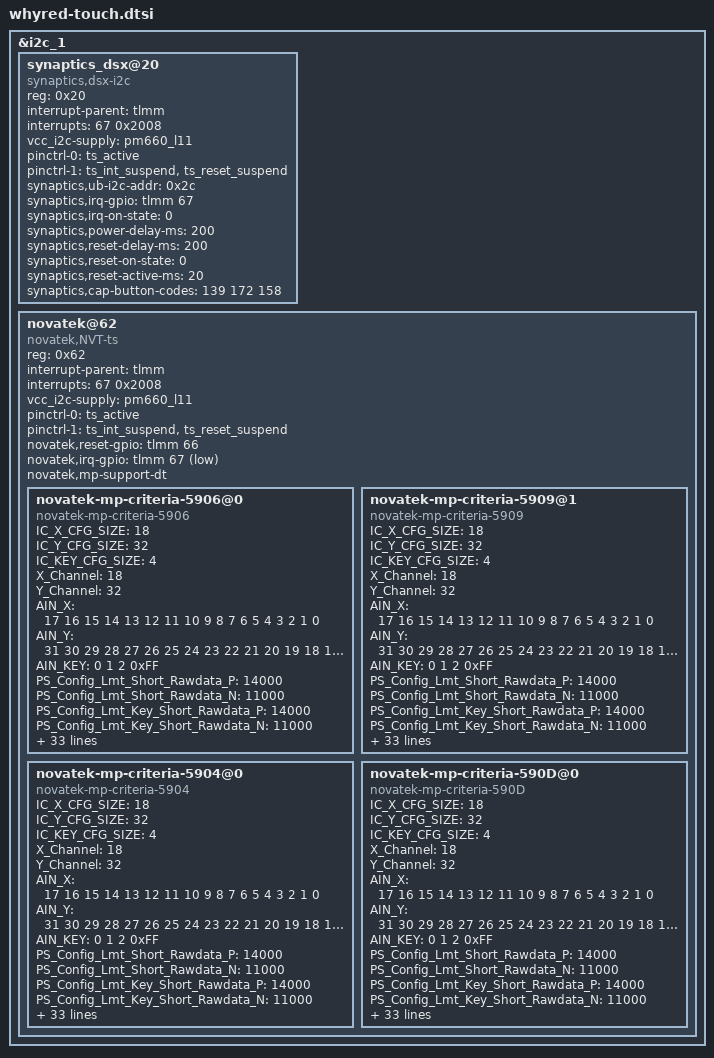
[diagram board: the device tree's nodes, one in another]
/* Copyright (c) 2017, The Linux Foundation. All rights reserved.
 * Copyright (C) 2019 XiaoMi, Inc.
 *
 * This program is free software; you can redistribute it and/or modify
 * it under the terms of the GNU General Public License version 2 and
 * only version 2 as published by the Free Software Foundation.
 *
 * This program is distributed in the hope that it will be useful,
 * but WITHOUT ANY WARRANTY; without even the implied warranty of
 * MERCHANTABILITY or FITNESS FOR A PARTICULAR PURPOSE.  See the
 * GNU General Public License for more details.
*/

&i2c_1 {
	status = "ok";

	synaptics_dsx@20 {
		compatible = "synaptics,dsx-i2c";
		reg = <0x20>;
		interrupt-parent = <&tlmm>;
		interrupts = <67 0x2008>;
		//vdd-supply = <&pm8994_lvs2>;
		//avdd-supply = <&pm8994_l22>;
		vcc_i2c-supply=<&pm660_l11>;
		pinctrl-names = "pmx_ts_active", "pmx_ts_suspend";
		pinctrl-0 = <&ts_active>;
		pinctrl-1 = <&ts_int_suspend &ts_reset_suspend>;
		//synaptics,pwr-reg-name = "avdd";
		//synaptics,bus-reg-name = "vdd";
		synaptics,ub-i2c-addr = <0x2c>;
		synaptics,irq-gpio = <&tlmm 67 0x2008>; /* IRQF_ONESHOT | IRQF_TRIGGER_LOW */
		//synaptics,reset-gpio = <&tlmm 66 0x00>;
		synaptics,irq-on-state = <0>;
		synaptics,power-delay-ms = <200>;
		synaptics,reset-delay-ms = <200>;
		synaptics,reset-on-state = <0>;
		synaptics,reset-active-ms = <20>;
		/* uncomment and update line below as appropriate if there are 0D buttons */
		synaptics,cap-button-codes = <139 172 158>; 
		/* uncomment and update lines below as appropriate if there are virtual buttons */
		/* synaptics,vir-button-codes = <102 100 900 100 60 158 300 900 100 60>; */
		/* synaptics,max-y-for-2d = <800>; */
	};

	/* Novatek device tree node */
	novatek@62 {
		compatible = "novatek,NVT-ts";
		reg = <0x62>;
		status = "ok";
		interrupt-parent = <&tlmm>;
		interrupts = <67 0x2008>;
		//vdd-supply = <&pm8994_lvs2>;
		//avdd-supply = <&pm8994_l22>;
		vcc_i2c-supply=<&pm660_l11>;
		pinctrl-names = "pmx_ts_active", "pmx_ts_suspend";
		pinctrl-0 = <&ts_active>;
		pinctrl-1 = <&ts_int_suspend &ts_reset_suspend>;
		novatek,reset-gpio = <&tlmm 66 0x00>;
		novatek,irq-gpio = <&tlmm 67 0x2001>;

		/* MP */
		novatek,mp-support-dt;
		//#if NVT_TOUCH_MP


		novatek-mp-criteria-5906@0 {
			#address-cells = <1>;
			#size-cells = <0>;
			compatible = "novatek-mp-criteria-5906";

			/* MP Config*/
			IC_X_CFG_SIZE = <18>;
			IC_Y_CFG_SIZE = <32>;
			IC_KEY_CFG_SIZE = <4>;
			X_Channel = <18>;
			Y_Channel = <32>;
			AIN_X = <17 16 15 14 13 12 11 10 9 8 7 6 5 4 3 2 1 0>;
			AIN_Y = <31 30 29 28 27 26 25 24 23 22 21 20 19 18 17 16 15
							14 13 12 11 10 9 8 7 6 5 4 3 2 1 0>;
			AIN_KEY = <0 1 2 0xFF>;

			/* MP Criteria */
			PS_Config_Lmt_Short_Rawdata_P = <14000>;
			PS_Config_Lmt_Short_Rawdata_N = <11000>;
			PS_Config_Lmt_Key_Short_Rawdata_P = <14000>;
			PS_Config_Lmt_Key_Short_Rawdata_N = <11000>;
			PS_Config_Lmt_Short_Diff_P = <6300>;
			PS_Config_Lmt_Short_Diff_N = <0>;
			PS_Config_Lmt_Key_Short_Diff_P = <6300>;
			PS_Config_Lmt_Key_Short_Diff_N = <0>;
			PS_Config_Lmt_Short_Base_P = <2000>;
			PS_Config_Lmt_Short_Base_N = <(-2000)>;
			PS_Config_Lmt_Key_Short_Base_P = <2000>;
			PS_Config_Lmt_Key_Short_Base_N = <(-2000)>;

			PS_Config_Lmt_Open_Rawdata_P = <
				7345 7376 7389 7403 7418 7442 7453 7432 7406 7365 7395 7412 7435 7452 7435 7420 7406 7392
				7342 7378 7393 7407 7425 7450 7458 7436 7407 7365 7393 7412 7437 7450 7433 7418 7402 7380
				7331 7365 7379 7394 7411 7438 7442 7420 7392 7377 7405 7425 7451 7462 7445 7428 7412 7387
				7333 7371 7387 7402 7420 7446 7448 7426 7397 7362 7389 7408 7434 7444 7425 7409 7393 7367
				7346 7385 7404 7420 7438 7464 7465 7442 7413 7379 7406 7427 7453 7459 7441 7425 7408 7376
				7334 7370 7390 7405 7423 7451 7447 7425 7395 7389 7417 7438 7466 7469 7450 7434 7417 7382
				7343 7380 7404 7420 7438 7466 7460 7437 7407 7381 7408 7429 7455 7458 7438 7422 7403 7367
				7351 7387 7413 7429 7448 7477 7467 7444 7413 7384 7412 7433 7460 7458 7440 7424 7403 7366
				7343 7377 7407 7424 7442 7470 7459 7435 7406 7408 7437 7459 7488 7483 7464 7447 7420 7381
				7351 7386 7417 7437 7456 7486 7470 7446 7416 7394 7423 7443 7472 7467 7446 7429 7399 7363
				7360 7396 7429 7452 7470 7502 7483 7459 7427 7412 7441 7464 7493 7482 7463 7444 7412 7374
				7348 7384 7416 7440 7460 7489 7466 7444 7413 7422 7453 7475 7506 7492 7473 7450 7416 7378
				7358 7396 7428 7458 7478 7509 7484 7459 7428 7417 7447 7470 7500 7486 7464 7437 7404 7366
				7372 7410 7443 7477 7497 7528 7500 7474 7441 7428 7459 7483 7515 7495 7474 7443 7410 7371
				7359 7397 7430 7463 7489 7515 7486 7461 7429 7451 7484 7509 7542 7517 7494 7459 7425 7385
				7373 7411 7445 7480 7507 7534 7503 7477 7443 7440 7472 7497 7530 7505 7476 7442 7408 7369
				7387 7427 7462 7499 7530 7556 7524 7496 7461 7462 7495 7522 7554 7525 7493 7457 7422 7381
				7369 7407 7441 7476 7516 7553 7525 7497 7462 7493 7530 7559 7582 7533 7495 7459 7423 7382
				7385 7425 7461 7497 7538 7574 7550 7520 7483 7493 7530 7559 7576 7529 7488 7452 7417 7375
				7403 7445 7482 7522 7564 7599 7577 7544 7505 7514 7553 7585 7594 7543 7502 7464 7427 7384
				7400 7441 7478 7517 7562 7591 7572 7540 7502 7548 7590 7621 7627 7573 7531 7489 7450 7406
				7421 7464 7504 7546 7592 7621 7600 7569 7526 7545 7587 7613 7615 7564 7519 7479 7440 7395
				7444 7490 7531 7575 7623 7650 7630 7598 7553 7577 7621 7647 7646 7589 7544 7502 7461 7413
				7442 7489 7531 7575 7626 7647 7626 7598 7553 7615 7664 7686 7682 7621 7572 7527 7485 7435
				7469 7518 7563 7611 7664 7684 7661 7636 7587 7624 7668 7690 7681 7620 7570 7525 7483 7432
				7501 7554 7602 7653 7711 7729 7702 7678 7625 7664 7706 7731 7717 7653 7599 7552 7507 7452
				7496 7549 7597 7650 7710 7721 7694 7671 7622 7714 7756 7784 7764 7694 7637 7586 7538 7479
				7325 7362 7392 7425 7461 7466 7454 7445 7416 7453 7471 7481 7460 7418 7384 7354 7325 7285
				7379 7422 7458 7497 7541 7545 7529 7516 7485 7527 7549 7564 7540 7490 7450 7414 7380 7334
				7419 7467 7508 7552 7604 7604 7583 7568 7537 7612 7641 7662 7633 7573 7526 7483 7444 7391
				7492 7549 7597 7652 7714 7714 7686 7665 7630 7678 7712 7738 7706 7636 7582 7534 7490 7432
				7652 7728 7798 7877 7968 7965 7917 7879 7823 7890 7941 7985 7944 7848 7770 7702 7641 7558>;

			PS_Config_Lmt_Open_Rawdata_N = <
				6834 6852 6860 6867 6876 6890 6896 6884 6869 6846 6863 6873 6886 6896 6886 6878 6869 6861
				6833 6853 6862 6870 6880 6895 6900 6887 6870 6846 6862 6873 6887 6895 6885 6876 6867 6854
				6826 6846 6854 6863 6872 6888 6890 6878 6861 6853 6869 6880 6895 6902 6892 6882 6873 6858
				6828 6849 6858 6867 6877 6892 6894 6881 6864 6844 6860 6871 6885 6891 6880 6871 6862 6847
				6835 6858 6868 6878 6888 6903 6903 6890 6873 6854 6870 6881 6897 6900 6890 6880 6870 6852
				6828 6848 6860 6869 6879 6895 6893 6880 6863 6859 6876 6888 6904 6905 6895 6886 6875 6855
				6833 6854 6868 6878 6888 6904 6900 6887 6870 6855 6871 6882 6898 6899 6888 6879 6868 6847
				6838 6858 6874 6883 6894 6910 6905 6891 6874 6857 6873 6885 6901 6899 6889 6880 6868 6847
				6833 6853 6870 6880 6890 6906 6900 6886 6869 6871 6887 6900 6916 6913 6903 6893 6877 6855
				6838 6858 6876 6887 6898 6915 6906 6892 6875 6863 6879 6891 6907 6904 6892 6883 6866 6845
				6843 6864 6882 6896 6906 6924 6914 6900 6882 6873 6890 6902 6919 6913 6902 6891 6873 6851
				6836 6857 6875 6889 6901 6917 6904 6891 6874 6879 6896 6909 6927 6919 6908 6895 6875 6853
				6842 6863 6882 6899 6911 6929 6914 6900 6882 6876 6893 6906 6924 6915 6903 6887 6868 6847
				6850 6872 6891 6910 6921 6939 6923 6909 6890 6882 6900 6914 6932 6921 6909 6891 6871 6849
				6843 6864 6883 6902 6917 6932 6916 6901 6883 6895 6914 6929 6948 6933 6920 6900 6880 6857
				6850 6872 6892 6912 6928 6943 6925 6910 6891 6889 6907 6922 6941 6926 6910 6890 6871 6848
				6859 6882 6902 6923 6941 6955 6937 6921 6901 6901 6921 6936 6955 6938 6920 6899 6879 6855
				6848 6870 6889 6910 6933 6954 6938 6922 6902 6919 6940 6957 6971 6943 6920 6900 6879 6855
				6858 6880 6901 6922 6945 6966 6952 6935 6914 6920 6941 6958 6967 6940 6917 6896 6875 6852
				6868 6892 6913 6936 6960 6981 6967 6949 6926 6931 6954 6972 6978 6948 6925 6903 6882 6857
				6866 6890 6911 6933 6959 6976 6965 6947 6925 6951 6975 6993 6997 6965 6941 6917 6895 6869
				6878 6903 6926 6950 6976 6993 6981 6963 6939 6949 6974 6988 6990 6960 6934 6912 6889 6863
				6891 6917 6941 6967 6994 7010 6998 6980 6954 6967 6993 7008 7007 6975 6949 6924 6901 6873
				6890 6917 6941 6966 6996 7008 6996 6980 6954 6990 7017 7030 7028 6993 6965 6939 6915 6886
				6905 6934 6959 6987 7018 7029 7016 7002 6974 6995 7020 7033 7027 6992 6964 6938 6914 6884
				6924 6954 6982 7012 7045 7055 7039 7026 6995 7018 7042 7056 7048 7011 6981 6953 6927 6896
				6921 6952 6979 7009 7044 7050 7035 7022 6994 7046 7070 7087 7075 7035 7002 6973 6945 6911
				6823 6844 6862 6880 6901 6904 6897 6892 6875 6896 6907 6912 6900 6876 6857 6840 6823 6800
				6854 6879 6899 6922 6947 6949 6940 6932 6915 6939 6952 6960 6946 6918 6895 6874 6855 6828
				6877 6905 6928 6953 6983 6983 6971 6962 6944 6988 7005 7016 7000 6965 6938 6914 6891 6861
				6919 6951 6979 7011 7046 7046 7031 7018 6998 7026 7045 7060 7042 7002 6971 6943 6917 6884
				7011 7055 7095 7140 7192 7191 7163 7141 7109 7148 7177 7202 7178 7123 7079 7040 7004 6957>;

			PS_Config_Lmt_FW_Rawdata_P = <
				1300 1300 1300 1300 1300 1300 1300 1300 1300 1300 1300 1300 1300 1300 1300 1300 1300 1300
				1300 1300 1300 1300 1300 1300 1300 1300 1300 1300 1300 1300 1300 1300 1300 1300 1300 1300
				1300 1300 1300 1300 1300 1300 1300 1300 1300 1300 1300 1300 1300 1300 1300 1300 1300 1300
				1300 1300 1300 1300 1300 1300 1300 1300 1300 1300 1300 1300 1300 1300 1300 1300 1300 1300
				1300 1300 1300 1300 1300 1300 1300 1300 1300 1300 1300 1300 1300 1300 1300 1300 1300 1300
				1300 1300 1300 1300 1300 1300 1300 1300 1300 1300 1300 1300 1300 1300 1300 1300 1300 1300
				1300 1300 1300 1300 1300 1300 1300 1300 1300 1300 1300 1300 1300 1300 1300 1300 1300 1300
				1300 1300 1300 1300 1300 1300 1300 1300 1300 1300 1300 1300 1300 1300 1300 1300 1300 1300
				1300 1300 1300 1300 1300 1300 1300 1300 1300 1300 1300 1300 1300 1300 1300 1300 1300 1300
				1300 1300 1300 1300 1300 1300 1300 1300 1300 1300 1300 1300 1300 1300 1300 1300 1300 1300
				1300 1300 1300 1300 1300 1300 1300 1300 1300 1300 1300 1300 1300 1300 1300 1300 1300 1300
				1300 1300 1300 1300 1300 1300 1300 1300 1300 1300 1300 1300 1300 1300 1300 1300 1300 1300
				1300 1300 1300 1300 1300 1300 1300 1300 1300 1300 1300 1300 1300 1300 1300 1300 1300 1300
				1300 1300 1300 1300 1300 1300 1300 1300 1300 1300 1300 1300 1300 1300 1300 1300 1300 1300
				1300 1300 1300 1300 1300 1300 1300 1300 1300 1300 1300 1300 1300 1300 1300 1300 1300 1300
				1300 1300 1300 1300 1300 1300 1300 1300 1300 1300 1300 1300 1300 1300 1300 1300 1300 1300
				1300 1300 1300 1300 1300 1300 1300 1300 1300 1300 1300 1300 1300 1300 1300 1300 1300 1300
				1300 1300 1300 1300 1300 1300 1300 1300 1300 1300 1300 1300 1300 1300 1300 1300 1300 1300
				1300 1300 1300 1300 1300 1300 1300 1300 1300 1300 1300 1300 1300 1300 1300 1300 1300 1300
				1300 1300 1300 1300 1300 1300 1300 1300 1300 1300 1300 1300 1300 1300 1300 1300 1300 1300
				1300 1300 1300 1300 1300 1300 1300 1300 1300 1300 1300 1300 1300 1300 1300 1300 1300 1300
				1300 1300 1300 1300 1300 1300 1300 1300 1300 1300 1300 1300 1300 1300 1300 1300 1300 1300
				1300 1300 1300 1300 1300 1300 1300 1300 1300 1300 1300 1300 1300 1300 1300 1300 1300 1300
				1300 1300 1300 1300 1300 1300 1300 1300 1300 1300 1300 1300 1300 1300 1300 1300 1300 1300
				1300 1300 1300 1300 1300 1300 1300 1300 1300 1300 1300 1300 1300 1300 1300 1300 1300 1300
				1300 1300 1300 1300 1300 1300 1300 1300 1300 1300 1300 1300 1300 1300 1300 1300 1300 1300
				1300 1300 1300 1300 1300 1300 1300 1300 1300 1300 1300 1300 1300 1300 1300 1300 1300 1300
				1300 1300 1300 1300 1300 1300 1300 1300 1300 1300 1300 1300 1300 1300 1300 1300 1300 1300
				1300 1300 1300 1300 1300 1300 1300 1300 1300 1300 1300 1300 1300 1300 1300 1300 1300 1300
				1300 1300 1300 1300 1300 1300 1300 1300 1300 1300 1300 1300 1300 1300 1300 1300 1300 1300
				1300 1300 1300 1300 1300 1300 1300 1300 1300 1300 1300 1300 1300 1300 1300 1300 1300 1300
				1300 1300 1300 1300 1300 1300 1300 1300 1300 1300 1300 1300 1300 1300 1300 1300 1300 1300>;
			PS_Config_Lmt_FW_Rawdata_N= <
				500 500 500 500 500 500 500 500 500 500 500 500 500 500 500 500 500 500
				500 500 500 500 500 500 500 500 500 500 500 500 500 500 500 500 500 500
				500 500 500 500 500 500 500 500 500 500 500 500 500 500 500 500 500 500
				500 500 500 500 500 500 500 500 500 500 500 500 500 500 500 500 500 500
				500 500 500 500 500 500 500 500 500 500 500 500 500 500 500 500 500 500
				500 500 500 500 500 500 500 500 500 500 500 500 500 500 500 500 500 500
				500 500 500 500 500 500 500 500 500 500 500 500 500 500 500 500 500 500
				500 500 500 500 500 500 500 500 500 500 500 500 500 500 500 500 500 500
				500 500 500 500 500 500 500 500 500 500 500 500 500 500 500 500 500 500
				500 500 500 500 500 500 500 500 500 500 500 500 500 500 500 500 500 500
				500 500 500 500 500 500 500 500 500 500 500 500 500 500 500 500 500 500
				500 500 500 500 500 500 500 500 500 500 500 500 500 500 500 500 500 500
				500 500 500 500 500 500 500 500 500 500 500 500 500 500 500 500 500 500
				500 500 500 500 500 500 500 500 500 500 500 500 500 500 500 500 500 500
				500 500 500 500 500 500 500 500 500 500 500 500 500 500 500 500 500 500
				500 500 500 500 500 500 500 500 500 500 500 500 500 500 500 500 500 500
				500 500 500 500 500 500 500 500 500 500 500 500 500 500 500 500 500 500
				500 500 500 500 500 500 500 500 500 500 500 500 500 500 500 500 500 500
				500 500 500 500 500 500 500 500 500 500 500 500 500 500 500 500 500 500
				500 500 500 500 500 500 500 500 500 500 500 500 500 500 500 500 500 500
				500 500 500 500 500 500 500 500 500 500 500 500 500 500 500 500 500 500
				500 500 500 500 500 500 500 500 500 500 500 500 500 500 500 500 500 500
				500 500 500 500 500 500 500 500 500 500 500 500 500 500 500 500 500 500
				500 500 500 500 500 500 500 500 500 500 500 500 500 500 500 500 500 500
				500 500 500 500 500 500 500 500 500 500 500 500 500 500 500 500 500 500
				500 500 500 500 500 500 500 500 500 500 500 500 500 500 500 500 500 500
				500 500 500 500 500 500 500 500 500 500 500 500 500 500 500 500 500 500
				500 500 500 500 500 500 500 500 500 500 500 500 500 500 500 500 500 500
				500 500 500 500 500 500 500 500 500 500 500 500 500 500 500 500 500 500
				500 500 500 500 500 500 500 500 500 500 500 500 500 500 500 500 500 500
				500 500 500 500 500 500 500 500 500 500 500 500 500 500 500 500 500 500
				500 500 500 500 500 500 500 500 500 500 500 500 500 500 500 500 500 500>;

			PS_Config_Lmt_FW_CC_P =<132>;
			PS_Config_Lmt_FW_CC_N =<74>;
			PS_Config_Lmt_Key_FW_CC_P =<38>;
			PS_Config_Lmt_Key_FW_CC_N =<9>;
			PS_Config_Lmt_FW_CC_I_P =<25>;
			PS_Config_Lmt_FW_CC_I_N =<0>;
			PS_Config_Lmt_FW_CC_Q_P =<25>;
			PS_Config_Lmt_FW_CC_Q_N =<0>;
			PS_Config_Lmt_Key_FW_CC_I_P =<25>;
			PS_Config_Lmt_Key_FW_CC_I_N =<0>;
			PS_Config_Lmt_Key_FW_CC_Q_P =<25>;
			PS_Config_Lmt_Key_FW_CC_Q_N =<0>;

			PS_Config_Lmt_FW_Diff_P =<35>;
			PS_Config_Lmt_FW_Diff_N =<(-35)>;
			PS_Config_Lmt_Key_FW_Diff_P =<35>;
			PS_Config_Lmt_Key_FW_Diff_N =<(-35)>;

		 PS_Config_Diff_Test_Frame =<50>;
		};

		novatek-mp-criteria-5909@1 {
			#address-cells = <1>;
			#size-cells = <0>;
			compatible = "novatek-mp-criteria-5909";

			/* MP Config*/
			IC_X_CFG_SIZE = <18>;
			IC_Y_CFG_SIZE = <32>;
			IC_KEY_CFG_SIZE = <4>;
			X_Channel = <18>;
			Y_Channel = <32>;
			AIN_X = <17 16 15 14 13 12 11 10 9 8 7 6 5 4 3 2 1 0>;
			AIN_Y = <31 30 29 28 27 26 25 24 23 22 21 20 19 18 17 16 15
							14 13 12 11 10 9 8 7 6 5 4 3 2 1 0>;
			AIN_KEY = <0 1 2 0xFF>;

			/* MP Criteria */
				PS_Config_Lmt_Short_Rawdata_P = <14000>;
				PS_Config_Lmt_Short_Rawdata_N = <11000>;
				PS_Config_Lmt_Key_Short_Rawdata_P = <14000>;
				PS_Config_Lmt_Key_Short_Rawdata_N = <11000>;
				PS_Config_Lmt_Short_Diff_P = <6300>;
				PS_Config_Lmt_Short_Diff_N = <0>;
				PS_Config_Lmt_Key_Short_Diff_P = <6300>;
				PS_Config_Lmt_Key_Short_Diff_N = <0>;
				PS_Config_Lmt_Short_Base_P = <2000>;
				PS_Config_Lmt_Short_Base_N = <(-2000)>;
				PS_Config_Lmt_Key_Short_Base_P = <2000>;
				PS_Config_Lmt_Key_Short_Base_N = <(-2000)>;

			PS_Config_Lmt_Open_Rawdata_P = <
				9032 9105 9084 9055 9049 9011 9030 9044 9078 9024 9036 9019 8992 8985 8995 9014 9018 9045
				8898 8951 8933 8904 8903 8864 8886 8896 8929 8874 8877 8863 8838 8831 8839 8854 8852 8871
				8864 8894 8879 8855 8857 8834 8844 8853 8885 8810 8810 8796 8774 8766 8776 8785 8784 8803
				8855 8896 8879 8858 8863 8834 8853 8864 8896 8848 8846 8834 8809 8812 8812 8817 8817 8818
				8809 8857 8828 8809 8813 8783 8805 8816 8847 8794 8791 8779 8754 8750 8755 8760 8768 8756
				8838 8875 8847 8830 8836 8816 8832 8842 8871 8806 8800 8792 8766 8761 8768 8768 8780 8769
				8785 8823 8792 8781 8787 8766 8783 8796 8824 8775 8769 8758 8733 8741 8739 8738 8747 8736
				8793 8817 8796 8784 8789 8771 8788 8801 8830 8783 8776 8764 8740 8739 8742 8741 8741 8736
				8758 8775 8770 8748 8754 8739 8755 8766 8795 8725 8719 8708 8683 8680 8683 8695 8680 8680
				8761 8775 8771 8749 8758 8743 8761 8774 8801 8758 8749 8737 8713 8722 8715 8727 8711 8713
				8711 8722 8717 8697 8700 8692 8709 8721 8748 8696 8686 8676 8652 8654 8652 8664 8649 8649
				8729 8734 8726 8712 8725 8709 8726 8739 8764 8702 8690 8678 8656 8655 8654 8662 8653 8653
				8661 8665 8648 8652 8652 8645 8663 8675 8695 8657 8643 8635 8611 8625 8618 8612 8612 8612
				8657 8661 8646 8654 8645 8641 8660 8671 8686 8650 8637 8627 8604 8608 8615 8603 8606 8601
				8607 8609 8597 8605 8608 8591 8611 8622 8635 8586 8574 8565 8543 8544 8551 8535 8542 8536
				8590 8592 8582 8591 8584 8580 8598 8609 8622 8592 8580 8569 8548 8563 8558 8543 8551 8544
				8524 8530 8522 8519 8521 8521 8540 8550 8564 8521 8509 8498 8478 8485 8476 8475 8485 8478
				8532 8536 8529 8527 8536 8537 8543 8553 8568 8522 8504 8493 8486 8478 8473 8473 8485 8476
				8460 8465 8459 8459 8457 8457 8476 8486 8500 8477 8458 8449 8430 8445 8430 8429 8442 8433
				8447 8453 8450 8449 8443 8446 8477 8476 8488 8458 8439 8441 8411 8418 8411 8412 8426 8412
				8392 8396 8397 8398 8402 8394 8424 8423 8433 8392 8373 8374 8347 8352 8347 8348 8361 8345
				8368 8374 8375 8376 8371 8373 8403 8401 8409 8391 8371 8375 8346 8362 8347 8351 8365 8345
				8297 8305 8308 8309 8299 8304 8325 8333 8339 8315 8296 8290 8271 8281 8272 8278 8291 8267
				8286 8297 8300 8302 8302 8295 8313 8336 8327 8297 8290 8269 8254 8264 8255 8260 8274 8248
				8217 8229 8232 8235 8224 8227 8245 8268 8258 8243 8238 8214 8199 8210 8200 8209 8222 8195
				8195 8208 8212 8213 8200 8206 8223 8247 8235 8218 8213 8190 8173 8186 8176 8187 8200 8170
				8143 8157 8161 8161 8159 8153 8170 8189 8181 8150 8144 8124 8108 8119 8108 8121 8134 8100
				8105 8119 8123 8121 8109 8114 8131 8142 8148 8137 8111 8100 8084 8095 8085 8100 8113 8076
				8047 8060 8065 8060 8046 8053 8070 8081 8091 8076 8045 8033 8017 8027 8018 8034 8049 8008
				8043 8056 8063 8054 8050 8047 8063 8075 8084 8060 8029 8017 7999 8011 8003 8021 8036 7990
				7996 8010 8016 8004 7990 7996 8013 8025 8031 8021 7991 7978 7969 7972 7966 7985 8002 7955
				8047 8060 8063 8047 8025 8039 8057 8070 8057 8047 8037 8022 8003 8016 8016 8037 8055 7985>;


			PS_Config_Lmt_Open_Rawdata_N = <
				7699 7739 7727 7711 7708 7688 7698 7705 7724 7695 7701 7692 7677 7674 7679 7690 7691 7706
				7627 7655 7646 7630 7630 7608 7620 7626 7643 7614 7615 7608 7595 7591 7595 7603 7602 7612
				7609 7625 7617 7604 7605 7593 7598 7602 7620 7580 7580 7572 7560 7556 7561 7566 7566 7576
				7604 7626 7617 7605 7608 7592 7603 7608 7626 7600 7599 7592 7579 7580 7581 7583 7583 7584
				7579 7605 7589 7579 7581 7565 7577 7583 7599 7571 7569 7563 7549 7547 7550 7553 7557 7551
				7595 7615 7599 7590 7594 7583 7591 7597 7612 7578 7574 7570 7556 7553 7557 7557 7564 7558
				7566 7587 7570 7564 7567 7556 7565 7572 7587 7561 7558 7552 7538 7543 7541 7541 7546 7540
				7570 7583 7572 7566 7568 7559 7568 7574 7590 7565 7561 7555 7542 7541 7543 7543 7542 7540
				7552 7560 7558 7546 7550 7541 7550 7556 7572 7534 7531 7524 7511 7510 7511 7518 7509 7509
				7553 7561 7558 7547 7551 7544 7553 7560 7575 7551 7546 7540 7527 7532 7529 7535 7526 7528
				7526 7532 7530 7519 7520 7516 7525 7532 7546 7518 7513 7507 7495 7495 7494 7501 7493 7493
				7536 7539 7534 7527 7534 7525 7534 7541 7555 7521 7515 7509 7496 7496 7495 7500 7495 7495
				7499 7502 7492 7494 7494 7491 7500 7507 7518 7497 7490 7485 7472 7480 7476 7473 7473 7473
				7497 7499 7491 7496 7491 7488 7499 7505 7513 7494 7487 7481 7469 7471 7475 7468 7470 7467
				7470 7471 7465 7469 7471 7462 7472 7478 7485 7459 7452 7448 7436 7436 7440 7432 7435 7432
				7461 7462 7457 7461 7458 7456 7466 7472 7478 7462 7456 7450 7438 7447 7444 7436 7440 7436
				7426 7429 7424 7423 7424 7424 7434 7440 7447 7424 7417 7411 7401 7405 7400 7399 7404 7401
				7430 7432 7428 7427 7432 7433 7436 7441 7449 7425 7415 7409 7405 7401 7398 7398 7404 7400
				7391 7394 7390 7390 7390 7390 7400 7405 7413 7400 7390 7385 7375 7383 7375 7375 7381 7376
				7384 7387 7386 7385 7382 7384 7400 7400 7406 7390 7380 7381 7365 7369 7365 7365 7373 7365
				7355 7357 7357 7358 7360 7355 7372 7371 7377 7355 7344 7345 7330 7333 7330 7331 7338 7329
				7342 7345 7345 7346 7343 7344 7360 7359 7364 7354 7343 7345 7330 7338 7330 7332 7340 7329
				7303 7308 7309 7310 7305 7307 7318 7323 7326 7313 7303 7300 7289 7295 7290 7293 7300 7287
				7297 7303 7305 7306 7306 7302 7312 7324 7319 7303 7300 7288 7280 7285 7281 7284 7291 7277
				7260 7266 7268 7270 7264 7266 7275 7288 7282 7274 7271 7259 7250 7256 7251 7256 7263 7248
				7248 7255 7258 7258 7251 7254 7263 7276 7270 7261 7258 7246 7237 7243 7238 7244 7251 7235
				7220 7228 7230 7230 7229 7226 7235 7245 7241 7224 7221 7210 7201 7207 7201 7209 7216 7197
				7200 7207 7210 7208 7202 7205 7214 7220 7223 7217 7203 7197 7189 7194 7189 7197 7204 7184
				7169 7176 7179 7176 7168 7172 7181 7187 7192 7184 7167 7161 7152 7158 7153 7162 7170 7147
				7167 7174 7177 7172 7170 7169 7177 7184 7189 7176 7159 7153 7143 7149 7145 7155 7163 7138
				7141 7149 7152 7146 7138 7141 7150 7157 7160 7155 7138 7132 7127 7128 7125 7135 7145 7119
				7168 7176 7178 7169 7157 7164 7174 7181 7174 7169 7163 7155 7145 7152 7152 7163 7173 7135>;

			PS_Config_Lmt_FW_Rawdata_P = <
				1600 1600 1600 1600 1600 1600 1600 1600 1600 1600 1600 1600 1600 1600 1600 1600 1600 1600
				1600 1600 1600 1600 1600 1600 1600 1600 1600 1600 1600 1600 1600 1600 1600 1600 1600 1600
				1600 1600 1600 1600 1600 1600 1600 1600 1600 1600 1600 1600 1600 1600 1600 1600 1600 1600
				1600 1600 1600 1600 1600 1600 1600 1600 1600 1600 1600 1600 1600 1600 1600 1600 1600 1600
				1600 1600 1600 1600 1600 1600 1600 1600 1600 1600 1600 1600 1600 1600 1600 1600 1600 1600
				1600 1600 1600 1600 1600 1600 1600 1600 1600 1600 1600 1600 1600 1600 1600 1600 1600 1600
				1600 1600 1600 1600 1600 1600 1600 1600 1600 1600 1600 1600 1600 1600 1600 1600 1600 1600
				1600 1600 1600 1600 1600 1600 1600 1600 1600 1600 1600 1600 1600 1600 1600 1600 1600 1600
				1600 1600 1600 1600 1600 1600 1600 1600 1600 1600 1600 1600 1600 1600 1600 1600 1600 1600
				1600 1600 1600 1600 1600 1600 1600 1600 1600 1600 1600 1600 1600 1600 1600 1600 1600 1600
				1600 1600 1600 1600 1600 1600 1600 1600 1600 1600 1600 1600 1600 1600 1600 1600 1600 1600
				1600 1600 1600 1600 1600 1600 1600 1600 1600 1600 1600 1600 1600 1600 1600 1600 1600 1600
				1600 1600 1600 1600 1600 1600 1600 1600 1600 1600 1600 1600 1600 1600 1600 1600 1600 1600
				1600 1600 1600 1600 1600 1600 1600 1600 1600 1600 1600 1600 1600 1600 1600 1600 1600 1600
				1600 1600 1600 1600 1600 1600 1600 1600 1600 1600 1600 1600 1600 1600 1600 1600 1600 1600
				1600 1600 1600 1600 1600 1600 1600 1600 1600 1600 1600 1600 1600 1600 1600 1600 1600 1600
				1600 1600 1600 1600 1600 1600 1600 1600 1600 1600 1600 1600 1600 1600 1600 1600 1600 1600
				1600 1600 1600 1600 1600 1600 1600 1600 1600 1600 1600 1600 1600 1600 1600 1600 1600 1600
				1600 1600 1600 1600 1600 1600 1600 1600 1600 1600 1600 1600 1600 1600 1600 1600 1600 1600
				1600 1600 1600 1600 1600 1600 1600 1600 1600 1600 1600 1600 1600 1600 1600 1600 1600 1600
				1600 1600 1600 1600 1600 1600 1600 1600 1600 1600 1600 1600 1600 1600 1600 1600 1600 1600
				1600 1600 1600 1600 1600 1600 1600 1600 1600 1600 1600 1600 1600 1600 1600 1600 1600 1600
				1600 1600 1600 1600 1600 1600 1600 1600 1600 1600 1600 1600 1600 1600 1600 1600 1600 1600
				1600 1600 1600 1600 1600 1600 1600 1600 1600 1600 1600 1600 1600 1600 1600 1600 1600 1600
				1600 1600 1600 1600 1600 1600 1600 1600 1600 1600 1600 1600 1600 1600 1600 1600 1600 1600
				1600 1600 1600 1600 1600 1600 1600 1600 1600 1600 1600 1600 1600 1600 1600 1600 1600 1600
				1600 1600 1600 1600 1600 1600 1600 1600 1600 1600 1600 1600 1600 1600 1600 1600 1600 1600
				1600 1600 1600 1600 1600 1600 1600 1600 1600 1600 1600 1600 1600 1600 1600 1600 1600 1600
				1600 1600 1600 1600 1600 1600 1600 1600 1600 1600 1600 1600 1600 1600 1600 1600 1600 1600
				1600 1600 1600 1600 1600 1600 1600 1600 1600 1600 1600 1600 1600 1600 1600 1600 1600 1600
				1600 1600 1600 1600 1600 1600 1600 1600 1600 1600 1600 1600 1600 1600 1600 1600 1600 1600
				1600 1600 1600 1600 1600 1600 1600 1600 1600 1600 1600 1600 1600 1600 1600 1600 1600 1600>;

			PS_Config_Lmt_FW_Rawdata_N= <
				800 800 800 800 800 800 800 800 800 800 800 800 800 800 800 800 800 800
				800 800 800 800 800 800 800 800 800 800 800 800 800 800 800 800 800 800
				800 800 800 800 800 800 800 800 800 800 800 800 800 800 800 800 800 800
				800 800 800 800 800 800 800 800 800 800 800 800 800 800 800 800 800 800
				800 800 800 800 800 800 800 800 800 800 800 800 800 800 800 800 800 800
				800 800 800 800 800 800 800 800 800 800 800 800 800 800 800 800 800 800
				800 800 800 800 800 800 800 800 800 800 800 800 800 800 800 800 800 800
				800 800 800 800 800 800 800 800 800 800 800 800 800 800 800 800 800 800
				800 800 800 800 800 800 800 800 800 800 800 800 800 800 800 800 800 800
				800 800 800 800 800 800 800 800 800 800 800 800 800 800 800 800 800 800
				800 800 800 800 800 800 800 800 800 800 800 800 800 800 800 800 800 800
				800 800 800 800 800 800 800 800 800 800 800 800 800 800 800 800 800 800
				800 800 800 800 800 800 800 800 800 800 800 800 800 800 800 800 800 800
				800 800 800 800 800 800 800 800 800 800 800 800 800 800 800 800 800 800
				800 800 800 800 800 800 800 800 800 800 800 800 800 800 800 800 800 800
				800 800 800 800 800 800 800 800 800 800 800 800 800 800 800 800 800 800
				800 800 800 800 800 800 800 800 800 800 800 800 800 800 800 800 800 800
				800 800 800 800 800 800 800 800 800 800 800 800 800 800 800 800 800 800
				800 800 800 800 800 800 800 800 800 800 800 800 800 800 800 800 800 800
				800 800 800 800 800 800 800 800 800 800 800 800 800 800 800 800 800 800
				800 800 800 800 800 800 800 800 800 800 800 800 800 800 800 800 800 800
				800 800 800 800 800 800 800 800 800 800 800 800 800 800 800 800 800 800
				800 800 800 800 800 800 800 800 800 800 800 800 800 800 800 800 800 800
				800 800 800 800 800 800 800 800 800 800 800 800 800 800 800 800 800 800
				800 800 800 800 800 800 800 800 800 800 800 800 800 800 800 800 800 800
				800 800 800 800 800 800 800 800 800 800 800 800 800 800 800 800 800 800
				800 800 800 800 800 800 800 800 800 800 800 800 800 800 800 800 800 800
				800 800 800 800 800 800 800 800 800 800 800 800 800 800 800 800 800 800
				800 800 800 800 800 800 800 800 800 800 800 800 800 800 800 800 800 800
				800 800 800 800 800 800 800 800 800 800 800 800 800 800 800 800 800 800
				800 800 800 800 800 800 800 800 800 800 800 800 800 800 800 800 800 800
				800 800 800 800 800 800 800 800 800 800 800 800 800 800 800 800 800 800>;

			PS_Config_Lmt_FW_CC_P =<118>;
			PS_Config_Lmt_FW_CC_N = <62>;
			PS_Config_Lmt_Key_FW_CC_P = <38>;
			PS_Config_Lmt_Key_FW_CC_N = <9>;
			PS_Config_Lmt_FW_CC_I_P = <25>;
			PS_Config_Lmt_FW_CC_I_N = <0>;
			PS_Config_Lmt_FW_CC_Q_P = <25>;
			PS_Config_Lmt_FW_CC_Q_N = <0>;
			PS_Config_Lmt_Key_FW_CC_I_P = <25>;
			PS_Config_Lmt_Key_FW_CC_I_N = <0>;
			PS_Config_Lmt_Key_FW_CC_Q_P = <25>;
			PS_Config_Lmt_Key_FW_CC_Q_N = <0>;

			PS_Config_Lmt_FW_Diff_P = <35>;
			PS_Config_Lmt_FW_Diff_N = <(-35)>;
			PS_Config_Lmt_Key_FW_Diff_P = <35>;
			PS_Config_Lmt_Key_FW_Diff_N = <(-35)>;

			PS_Config_Diff_Test_Frame = <50>;

		};

		novatek-mp-criteria-5904@0 {
			#address-cells = <1>;
			#size-cells = <0>;
			compatible = "novatek-mp-criteria-5904";

			/* MP Config */
			IC_X_CFG_SIZE = <18>;
			IC_Y_CFG_SIZE = <32>;
			IC_KEY_CFG_SIZE = <4>;
			X_Channel = <18>;
			Y_Channel = <32>;
			AIN_X = <17 16 15 14 13 12 11 10 9 8 7 6 5 4 3 2 1 0>;
			AIN_Y = <31 30 29 28 27 26 25 24 23 22 21 20 19 18 17 16 15
								14 13 12 11 10 9 8 7 6 5 4 3 2 1 0>;
			AIN_KEY = <0 1 2 0xFF>;

			/* MP Criteria */
			PS_Config_Lmt_Short_Rawdata_P = <14000>;
			PS_Config_Lmt_Short_Rawdata_N = <11000>;
			PS_Config_Lmt_Key_Short_Rawdata_P = <14000>;
			PS_Config_Lmt_Key_Short_Rawdata_N = <11000>;
			PS_Config_Lmt_Short_Diff_P = <6300>;
			PS_Config_Lmt_Short_Diff_N = <0>;
			PS_Config_Lmt_Key_Short_Diff_P = <6300>;
			PS_Config_Lmt_Key_Short_Diff_N = <0>;
			PS_Config_Lmt_Short_Base_P = <2000>;
			PS_Config_Lmt_Short_Base_N = <(-2000)>;
			PS_Config_Lmt_Key_Short_Base_P = <2000>;
			PS_Config_Lmt_Key_Short_Base_N = <(-2000)>;

			PS_Config_Lmt_Open_Rawdata_P = <
				7336 7373 7385 7397 7412 7435 7446 7427 7402 7363 7393 7410 7431 7448 7430 7415 7400 7387
				7333 7372 7387 7399 7416 7441 7448 7428 7401 7367 7396 7414 7438 7451 7431 7416 7399 7379
				7326 7363 7377 7390 7406 7435 7437 7417 7390 7377 7406 7425 7449 7458 7441 7423 7407 7384
				7330 7370 7384 7397 7414 7440 7443 7422 7394 7360 7388 7406 7430 7440 7420 7403 7387 7361
				7341 7383 7401 7415 7433 7458 7459 7437 7409 7376 7405 7425 7450 7454 7436 7419 7402 7371
				7335 7373 7393 7405 7423 7451 7447 7425 7397 7386 7414 7435 7462 7464 7445 7427 7409 7376
				7348 7387 7410 7425 7442 7471 7464 7441 7413 7384 7413 7432 7458 7460 7440 7423 7403 7367
				7354 7392 7417 7431 7450 7478 7468 7445 7417 7388 7415 7436 7461 7460 7440 7424 7401 7366
				7341 7377 7405 7420 7438 7465 7455 7431 7404 7405 7435 7456 7483 7477 7457 7439 7413 7376
				7350 7386 7417 7434 7452 7482 7467 7444 7414 7399 7427 7447 7474 7469 7447 7429 7400 7364
				7359 7397 7427 7448 7466 7498 7480 7456 7426 7412 7443 7464 7491 7480 7460 7440 7408 7371
				7348 7385 7416 7438 7459 7487 7465 7443 7414 7424 7455 7478 7507 7492 7472 7447 7414 7377
				7363 7401 7432 7459 7479 7512 7486 7461 7432 7420 7451 7472 7501 7485 7464 7436 7404 7366
				7371 7410 7442 7473 7493 7524 7497 7472 7440 7430 7461 7484 7514 7494 7473 7440 7407 7369
				7364 7403 7433 7465 7490 7517 7489 7464 7434 7458 7491 7516 7548 7522 7497 7461 7428 7389
				7372 7411 7444 7476 7503 7530 7500 7474 7442 7441 7473 7498 7528 7504 7474 7438 7406 7367
				7387 7426 7461 7495 7526 7552 7521 7494 7459 7465 7500 7525 7556 7526 7494 7456 7423 7381
				7369 7408 7441 7473 7513 7550 7523 7495 7461 7496 7533 7561 7584 7534 7495 7459 7424 7382
				7392 7432 7467 7502 7542 7580 7555 7524 7488 7499 7537 7564 7581 7533 7491 7456 7420 7379
				7406 7447 7484 7521 7562 7598 7574 7543 7505 7520 7559 7590 7599 7547 7506 7467 7430 7389
				7409 7451 7487 7524 7569 7599 7580 7547 7509 7552 7594 7624 7630 7575 7532 7490 7452 7407
				7426 7469 7508 7549 7595 7624 7602 7572 7528 7551 7592 7617 7620 7567 7522 7482 7443 7397
				7444 7490 7530 7573 7622 7650 7628 7596 7551 7587 7630 7657 7656 7598 7552 7508 7469 7420
				7446 7492 7534 7577 7629 7651 7628 7600 7554 7621 7670 7691 7687 7626 7576 7530 7489 7437
				7479 7529 7574 7621 7676 7696 7671 7644 7595 7635 7680 7702 7693 7631 7581 7535 7492 7439
				7508 7561 7610 7660 7719 7737 7708 7683 7629 7675 7717 7742 7730 7663 7610 7561 7516 7459
				7502 7556 7604 7658 7718 7729 7701 7676 7626 7724 7768 7797 7777 7706 7647 7595 7547 7486
				7327 7364 7394 7426 7463 7467 7455 7445 7415 7461 7479 7489 7468 7425 7392 7360 7331 7290
				7385 7427 7462 7500 7546 7549 7533 7518 7487 7534 7557 7572 7547 7496 7457 7420 7385 7338
				7430 7479 7519 7563 7615 7616 7593 7577 7544 7623 7653 7675 7647 7586 7536 7493 7454 7399
				7506 7563 7613 7669 7732 7732 7703 7679 7641 7695 7730 7758 7727 7656 7600 7550 7505 7445
				7667 7742 7813 7892 7988 7981 7930 7890 7827 7907 7959 8008 7967 7868 7788 7721 7657 7577
				13000 13000 13000>;

			PS_Config_Lmt_Open_Rawdata_N = <
				6829 6851 6858 6864 6873 6886 6893 6881 6867 6845 6862 6872 6884 6893 6883 6875 6866 6859
				6827 6850 6858 6865 6875 6889 6894 6882 6866 6847 6864 6874 6888 6895 6884 6875 6865 6854
				6824 6845 6853 6860 6869 6886 6887 6876 6860 6853 6869 6880 6894 6899 6890 6879 6870 6857
				6825 6848 6857 6864 6874 6889 6891 6878 6863 6843 6859 6869 6883 6889 6877 6867 6859 6844
				6832 6856 6867 6874 6885 6900 6900 6887 6871 6852 6869 6880 6894 6897 6887 6877 6867 6849
				6829 6850 6862 6869 6879 6895 6893 6880 6864 6858 6874 6886 6901 6903 6892 6882 6871 6852
				6836 6858 6872 6880 6890 6906 6903 6889 6873 6857 6873 6884 6899 6900 6889 6879 6868 6847
				6840 6862 6876 6884 6895 6911 6905 6892 6876 6859 6875 6886 6901 6900 6889 6880 6867 6846
				6832 6852 6869 6877 6888 6903 6897 6884 6868 6869 6886 6898 6914 6910 6899 6889 6873 6852
				6837 6858 6876 6885 6896 6913 6904 6891 6874 6866 6881 6893 6909 6906 6893 6883 6866 6845
				6842 6864 6881 6894 6904 6922 6912 6898 6881 6873 6890 6902 6919 6912 6901 6889 6870 6849
				6836 6857 6875 6888 6900 6916 6903 6890 6874 6880 6898 6911 6927 6919 6907 6893 6874 6853
				6845 6866 6884 6900 6911 6930 6916 6901 6884 6878 6895 6907 6924 6915 6903 6886 6868 6846
				6850 6872 6890 6908 6919 6937 6921 6907 6889 6883 6901 6914 6932 6920 6908 6889 6870 6848
				6845 6867 6885 6903 6918 6933 6917 6903 6885 6900 6918 6932 6951 6936 6921 6901 6882 6859
				6850 6872 6891 6910 6925 6941 6924 6908 6890 6889 6908 6922 6940 6926 6908 6888 6869 6847
				6859 6881 6901 6921 6939 6953 6936 6920 6900 6903 6923 6938 6956 6938 6920 6898 6879 6855
				6848 6871 6890 6908 6931 6952 6937 6921 6901 6921 6942 6959 6972 6943 6920 6900 6880 6856
				6861 6885 6904 6924 6948 6969 6955 6937 6917 6923 6945 6960 6970 6942 6918 6898 6877 6854
				6869 6893 6914 6936 6959 6980 6966 6948 6926 6935 6957 6975 6980 6950 6927 6904 6883 6859
				6871 6895 6916 6937 6963 6980 6969 6951 6929 6954 6977 6995 6998 6966 6942 6918 6896 6870
				6881 6906 6928 6952 6978 6995 6982 6965 6940 6953 6976 6991 6992 6962 6936 6913 6891 6864
				6891 6917 6941 6966 6994 7009 6997 6979 6953 6974 6998 7013 7013 6980 6953 6928 6906 6877
				6892 6919 6943 6968 6998 7010 6997 6981 6954 6993 7021 7033 7031 6996 6967 6941 6917 6887
				6911 6940 6966 6993 7025 7036 7022 7006 6978 7001 7027 7040 7035 6999 6970 6943 6919 6888
				6928 6959 6986 7016 7049 7059 7043 7029 6998 7024 7048 7063 7055 7017 6987 6959 6933 6900
				6924 6956 6983 7014 7049 7055 7039 7025 6996 7052 7077 7094 7083 7042 7008 6978 6950 6915
				6824 6845 6863 6881 6902 6905 6897 6892 6875 6901 6911 6917 6905 6880 6861 6843 6826 6803
				6857 6881 6902 6924 6950 6951 6942 6934 6916 6943 6956 6965 6951 6921 6899 6877 6858 6830
				6883 6911 6934 6959 6990 6990 6977 6968 6948 6994 7012 7024 7008 6973 6944 6919 6897 6865
				6927 6960 6988 7020 7057 7057 7040 7026 7005 7035 7056 7072 7054 7013 6981 6952 6926 6892
				7019 7063 7103 7149 7204 7200 7171 7147 7112 7158 7188 7215 7192 7135 7089 7051 7014 6968
				6500 6500 6500>;

			PS_Config_Lmt_FW_Rawdata_P = <
				1300 1300 1300 1300 1300 1300 1300 1300 1300 1300 1300 1300 1300 1300 1300 1300 1300 1300
				1300 1300 1300 1300 1300 1300 1300 1300 1300 1300 1300 1300 1300 1300 1300 1300 1300 1300
				1300 1300 1300 1300 1300 1300 1300 1300 1300 1300 1300 1300 1300 1300 1300 1300 1300 1300
				1300 1300 1300 1300 1300 1300 1300 1300 1300 1300 1300 1300 1300 1300 1300 1300 1300 1300
				1300 1300 1300 1300 1300 1300 1300 1300 1300 1300 1300 1300 1300 1300 1300 1300 1300 1300
				1300 1300 1300 1300 1300 1300 1300 1300 1300 1300 1300 1300 1300 1300 1300 1300 1300 1300
				1300 1300 1300 1300 1300 1300 1300 1300 1300 1300 1300 1300 1300 1300 1300 1300 1300 1300
				1300 1300 1300 1300 1300 1300 1300 1300 1300 1300 1300 1300 1300 1300 1300 1300 1300 1300
				1300 1300 1300 1300 1300 1300 1300 1300 1300 1300 1300 1300 1300 1300 1300 1300 1300 1300
				1300 1300 1300 1300 1300 1300 1300 1300 1300 1300 1300 1300 1300 1300 1300 1300 1300 1300
				1300 1300 1300 1300 1300 1300 1300 1300 1300 1300 1300 1300 1300 1300 1300 1300 1300 1300
				1300 1300 1300 1300 1300 1300 1300 1300 1300 1300 1300 1300 1300 1300 1300 1300 1300 1300
				1300 1300 1300 1300 1300 1300 1300 1300 1300 1300 1300 1300 1300 1300 1300 1300 1300 1300
				1300 1300 1300 1300 1300 1300 1300 1300 1300 1300 1300 1300 1300 1300 1300 1300 1300 1300
				1300 1300 1300 1300 1300 1300 1300 1300 1300 1300 1300 1300 1300 1300 1300 1300 1300 1300
				1300 1300 1300 1300 1300 1300 1300 1300 1300 1300 1300 1300 1300 1300 1300 1300 1300 1300
				1300 1300 1300 1300 1300 1300 1300 1300 1300 1300 1300 1300 1300 1300 1300 1300 1300 1300
				1300 1300 1300 1300 1300 1300 1300 1300 1300 1300 1300 1300 1300 1300 1300 1300 1300 1300
				1300 1300 1300 1300 1300 1300 1300 1300 1300 1300 1300 1300 1300 1300 1300 1300 1300 1300
				1300 1300 1300 1300 1300 1300 1300 1300 1300 1300 1300 1300 1300 1300 1300 1300 1300 1300
				1300 1300 1300 1300 1300 1300 1300 1300 1300 1300 1300 1300 1300 1300 1300 1300 1300 1300
				1300 1300 1300 1300 1300 1300 1300 1300 1300 1300 1300 1300 1300 1300 1300 1300 1300 1300
				1300 1300 1300 1300 1300 1300 1300 1300 1300 1300 1300 1300 1300 1300 1300 1300 1300 1300
				1300 1300 1300 1300 1300 1300 1300 1300 1300 1300 1300 1300 1300 1300 1300 1300 1300 1300
				1300 1300 1300 1300 1300 1300 1300 1300 1300 1300 1300 1300 1300 1300 1300 1300 1300 1300
				1300 1300 1300 1300 1300 1300 1300 1300 1300 1300 1300 1300 1300 1300 1300 1300 1300 1300
				1300 1300 1300 1300 1300 1300 1300 1300 1300 1300 1300 1300 1300 1300 1300 1300 1300 1300
				1300 1300 1300 1300 1300 1300 1300 1300 1300 1300 1300 1300 1300 1300 1300 1300 1300 1300
				1300 1300 1300 1300 1300 1300 1300 1300 1300 1300 1300 1300 1300 1300 1300 1300 1300 1300
				1300 1300 1300 1300 1300 1300 1300 1300 1300 1300 1300 1300 1300 1300 1300 1300 1300 1300
				1300 1300 1300 1300 1300 1300 1300 1300 1300 1300 1300 1300 1300 1300 1300 1300 1300 1300
				1300 1300 1300 1300 1300 1300 1300 1300 1300 1300 1300 1300 1300 1300 1300 1300 1300 1300
				2000 2000 2000>;

			PS_Config_Lmt_FW_Rawdata_N= <
				500 500 500 500 500 500 500 500 500 500 500 500 500 500 500 500 500 500
				500 500 500 500 500 500 500 500 500 500 500 500 500 500 500 500 500 500
				500 500 500 500 500 500 500 500 500 500 500 500 500 500 500 500 500 500
				500 500 500 500 500 500 500 500 500 500 500 500 500 500 500 500 500 500
				500 500 500 500 500 500 500 500 500 500 500 500 500 500 500 500 500 500
				500 500 500 500 500 500 500 500 500 500 500 500 500 500 500 500 500 500
				500 500 500 500 500 500 500 500 500 500 500 500 500 500 500 500 500 500
				500 500 500 500 500 500 500 500 500 500 500 500 500 500 500 500 500 500
				500 500 500 500 500 500 500 500 500 500 500 500 500 500 500 500 500 500
				500 500 500 500 500 500 500 500 500 500 500 500 500 500 500 500 500 500
				500 500 500 500 500 500 500 500 500 500 500 500 500 500 500 500 500 500
				500 500 500 500 500 500 500 500 500 500 500 500 500 500 500 500 500 500
				500 500 500 500 500 500 500 500 500 500 500 500 500 500 500 500 500 500
				500 500 500 500 500 500 500 500 500 500 500 500 500 500 500 500 500 500
				500 500 500 500 500 500 500 500 500 500 500 500 500 500 500 500 500 500
				500 500 500 500 500 500 500 500 500 500 500 500 500 500 500 500 500 500
				500 500 500 500 500 500 500 500 500 500 500 500 500 500 500 500 500 500
				500 500 500 500 500 500 500 500 500 500 500 500 500 500 500 500 500 500
				500 500 500 500 500 500 500 500 500 500 500 500 500 500 500 500 500 500
				500 500 500 500 500 500 500 500 500 500 500 500 500 500 500 500 500 500
				500 500 500 500 500 500 500 500 500 500 500 500 500 500 500 500 500 500
				500 500 500 500 500 500 500 500 500 500 500 500 500 500 500 500 500 500
				500 500 500 500 500 500 500 500 500 500 500 500 500 500 500 500 500 500
				500 500 500 500 500 500 500 500 500 500 500 500 500 500 500 500 500 500
				500 500 500 500 500 500 500 500 500 500 500 500 500 500 500 500 500 500
				500 500 500 500 500 500 500 500 500 500 500 500 500 500 500 500 500 500
				500 500 500 500 500 500 500 500 500 500 500 500 500 500 500 500 500 500
				500 500 500 500 500 500 500 500 500 500 500 500 500 500 500 500 500 500
				500 500 500 500 500 500 500 500 500 500 500 500 500 500 500 500 500 500
				500 500 500 500 500 500 500 500 500 500 500 500 500 500 500 500 500 500
				500 500 500 500 500 500 500 500 500 500 500 500 500 500 500 500 500 500
				500 500 500 500 500 500 500 500 500 500 500 500 500 500 500 500 500 500
				400 400 400>;

			PS_Config_Lmt_FW_CC_P = <119>;
			PS_Config_Lmt_FW_CC_N = <72>;
			PS_Config_Lmt_Key_FW_CC_P = <38>;
			PS_Config_Lmt_Key_FW_CC_N = <9>;

			PS_Config_Lmt_FW_CC_I_P = <25>;
			PS_Config_Lmt_FW_CC_I_N = <0>;
			PS_Config_Lmt_FW_CC_Q_P = <25>;
			PS_Config_Lmt_FW_CC_Q_N = <0>;
			PS_Config_Lmt_Key_FW_CC_I_P = <25>;
			PS_Config_Lmt_Key_FW_CC_I_N = <0>;
			PS_Config_Lmt_Key_FW_CC_Q_P = <25>;
			PS_Config_Lmt_Key_FW_CC_Q_N = <0>;

			PS_Config_Lmt_FW_Diff_P = <35>;
			PS_Config_Lmt_FW_Diff_N = <(-35)>;
			PS_Config_Lmt_Key_FW_Diff_P = <35>;
			PS_Config_Lmt_Key_FW_Diff_N = <(-35)>;

			PS_Config_Diff_Test_Frame = <50>;
		};

		novatek-mp-criteria-590D@0 {
			#address-cells = <1>;
			#size-cells = <0>;
			compatible = "novatek-mp-criteria-590D";

			/* MP Config */
			IC_X_CFG_SIZE = <18>;
			IC_Y_CFG_SIZE = <32>;
			IC_KEY_CFG_SIZE = <4>;
			X_Channel = <18>;
			Y_Channel = <32>;
			AIN_X = <17 16 15 14 13 12 11 10 9 8 7 6 5 4 3 2 1 0>;
			AIN_Y = <31 30 29 28 27 26 25 24 23 22 21 20 19 18 17 16 15
								14 13 12 11 10 9 8 7 6 5 4 3 2 1 0>;
			AIN_KEY = <0 1 2 0xFF>;

			/* MP Criteria */
			PS_Config_Lmt_Short_Rawdata_P = <14000>;
			PS_Config_Lmt_Short_Rawdata_N = <11000>;
			PS_Config_Lmt_Key_Short_Rawdata_P = <14000>;
			PS_Config_Lmt_Key_Short_Rawdata_N = <11000>;
			PS_Config_Lmt_Short_Diff_P = <6300>;
			PS_Config_Lmt_Short_Diff_N = <0>;
			PS_Config_Lmt_Key_Short_Diff_P = <6300>;
			PS_Config_Lmt_Key_Short_Diff_N = <0>;
			PS_Config_Lmt_Short_Base_P = <2000>;
			PS_Config_Lmt_Short_Base_N = <(-2000)>;
			PS_Config_Lmt_Key_Short_Base_P = <2000>;
			PS_Config_Lmt_Key_Short_Base_N = <(-2000)>;

			PS_Config_Lmt_Open_Rawdata_P = <
				10420	10685	10681	10666	10645	10612	10616	10650	10676	10723	10725	10694	10660	10655	10675	10691	10694	10605
				10354	10498	10497	10486	10470	10441	10449	10478	10499	10535	10527	10501	10471	10463	10481	10491	10491	10480
				10407	10533	10535	10527	10511	10496	10495	10524	10542	10552	10541	10516	10488	10478	10498	10505	10503	10491
				10312	10449	10449	10441	10427	10404	10413	10442	10459	10491	10480	10457	10427	10431	10439	10446	10445	10416
				10344	10489	10478	10472	10459	10432	10447	10477	10492	10521	10511	10487	10457	10454	10468	10475	10483	10442
				10286	10418	10407	10400	10390	10369	10379	10409	10424	10437	10425	10400	10370	10367	10384	10388	10397	10358
				10296	10425	10413	10408	10397	10373	10389	10419	10434	10468	10457	10430	10401	10410	10416	10418	10427	10384
				10206	10320	10318	10312	10303	10280	10297	10326	10340	10374	10361	10335	10305	10309	10322	10324	10322	10291
				10243	10348	10363	10346	10336	10312	10332	10360	10376	10380	10369	10343	10311	10314	10329	10344	10326	10296
				10139	10238	10253	10237	10226	10203	10223	10254	10269	10301	10287	10261	10231	10247	10250	10263	10245	10214
				10148	10246	10261	10245	10229	10210	10233	10264	10279	10298	10284	10257	10226	10236	10248	10261	10244	10209
				10064	10155	10167	10155	10150	10121	10145	10176	10191	10192	10177	10149	10119	10127	10142	10152	10138	10104
				10060	10148	10151	10156	10137	10114	10142	10172	10186	10221	10205	10178	10147	10169	10179	10173	10169	10129
				9957	10038	10042	10053	10024	10006	10034	10066	10078	10091	10075	10048	10017	10033	10058	10046	10042	10000
				9962	10041	10045	10055	10039	10010	10040	10071	10083	10083	10066	10039	10008	10023	10051	10038	10037	9990
				9849	9923	9928	9939	9912	9895	9924	9954	9966	9988	9971	9944	9914	9942	9959	9948	9945	9895
				9824	9897	9903	9902	9887	9870	9901	9927	9944	9957	9940	9912	9883	9905	9916	9918	9911	9860
				9731	9799	9804	9805	9797	9783	9799	9824	9842	9851	9833	9806	9793	9803	9817	9822	9816	9759
				9708	9775	9781	9780	9762	9746	9777	9800	9817	9839	9822	9797	9773	9805	9809	9813	9807	9744
				9593	9658	9664	9662	9642	9632	9673	9684	9701	9710	9693	9680	9649	9670	9682	9687	9684	9614
				9587	9650	9657	9655	9646	9626	9666	9678	9695	9679	9660	9645	9619	9638	9654	9660	9655	9581
				9452	9516	9521	9519	9502	9494	9533	9543	9558	9584	9566	9554	9528	9557	9561	9568	9565	9484
				9417	9483	9488	9484	9464	9461	9491	9510	9526	9531	9512	9491	9476	9500	9511	9518	9516	9430
				9318	9383	9388	9384	9376	9363	9389	9423	9424	9408	9400	9367	9358	9381	9392	9400	9397	9306
				9260	9325	9330	9326	9309	9307	9333	9366	9366	9371	9366	9330	9324	9347	9359	9368	9365	9267
				9136	9201	9205	9201	9181	9184	9210	9243	9242	9241	9236	9201	9196	9219	9230	9240	9238	9134
				9103	9169	9173	9169	9160	9155	9180	9206	9211	9192	9187	9157	9154	9176	9187	9198	9195	9081
				8914	8979	8983	8976	8958	8962	8988	9006	9023	9035	9009	8987	8986	9007	9020	9031	9028	8908
				8861	8927	8931	8924	8903	8911	8936	8955	8973	8974	8942	8920	8918	8941	8955	8966	8964	8834
				8755	8821	8823	8817	8806	8804	8828	8848	8862	8847	8814	8792	8790	8814	8829	8841	8837	8699
				8707	8773	8775	8767	8746	8754	8780	8800	8809	8816	8782	8760	8768	8786	8801	8815	8813	8668
				10320	10027	10026	10008	9974	9991	10020	10046	10030	10044	10018	9994	10000	10029	10048	10064	10067	9122
				13000 13000 13000>;

			PS_Config_Lmt_Open_Rawdata_N = <
				8298	8432	8430	8422	8411	8395	8397	8414	8427	8451	8452	8436	8419	8417	8426	8434	8436	8391
				8265	8337	8337	8331	8323	8309	8313	8328	8338	8356	8352	8339	8324	8320	8329	8334	8334	8328
				8292	8355	8356	8352	8344	8336	8336	8351	8359	8364	8359	8346	8332	8327	8337	8341	8340	8334
				8244	8313	8313	8309	8302	8290	8295	8309	8318	8334	8328	8317	8302	8304	8308	8311	8311	8296
				8260	8333	8327	8324	8318	8304	8312	8327	8334	8349	8344	8332	8317	8315	8322	8326	8330	8309
				8230	8297	8291	8288	8283	8272	8278	8292	8300	8307	8301	8288	8273	8271	8280	8282	8287	8267
				8236	8300	8294	8292	8287	8274	8283	8297	8305	8322	8317	8303	8289	8293	8296	8297	8301	8280
				8190	8248	8247	8244	8239	8227	8236	8251	8258	8275	8268	8255	8240	8242	8249	8249	8249	8233
				8209	8262	8269	8261	8256	8244	8254	8268	8276	8278	8273	8259	8243	8245	8252	8260	8251	8235
				8156	8207	8214	8206	8200	8189	8199	8215	8222	8238	8231	8218	8203	8211	8213	8219	8210	8194
				8161	8210	8218	8210	8202	8192	8204	8219	8227	8237	8230	8216	8201	8205	8212	8218	8209	8192
				8119	8164	8170	8164	8162	8148	8160	8175	8182	8183	8176	8162	8147	8151	8158	8163	8156	8139
				8117	8161	8162	8165	8155	8144	8158	8173	8180	8198	8190	8176	8160	8171	8177	8173	8172	8151
				8065	8106	8108	8113	8099	8089	8104	8120	8126	8132	8124	8111	8095	8103	8116	8110	8108	8086
				8068	8107	8109	8114	8106	8091	8107	8122	8128	8128	8120	8106	8091	8098	8112	8106	8105	8081
				8011	8048	8050	8056	8042	8033	8048	8063	8069	8081	8072	8058	8043	8057	8066	8060	8059	8033
				7998	8034	8037	8037	8029	8021	8037	8050	8058	8065	8056	8042	8028	8039	8044	8045	8042	8016
				7951	7985	7988	7988	7984	7977	7985	7998	8007	8012	8003	7989	7982	7987	7994	7997	7994	7965
				7939	7973	7976	7976	7967	7958	7974	7986	7995	8006	7997	7984	7972	7988	7990	7992	7989	7958
				7881	7914	7917	7916	7906	7901	7922	7927	7936	7941	7932	7925	7910	7920	7926	7929	7927	7892
				7879	7910	7914	7913	7908	7898	7918	7924	7933	7925	7915	7908	7894	7904	7912	7915	7913	7875
				7811	7843	7845	7844	7836	7831	7851	7856	7864	7877	7868	7862	7849	7863	7866	7869	7867	7827
				7793	7826	7828	7827	7817	7815	7830	7840	7847	7850	7840	7830	7823	7835	7840	7844	7842	7799
				7743	7776	7778	7776	7772	7765	7779	7796	7796	7788	7784	7768	7763	7775	7780	7784	7783	7737
				7714	7746	7749	7747	7738	7738	7750	7767	7767	7770	7767	7749	7746	7758	7763	7768	7767	7717
				7651	7684	7686	7684	7674	7676	7689	7705	7705	7704	7702	7684	7682	7693	7698	7704	7703	7650
				7635	7668	7670	7668	7663	7661	7673	7687	7689	7680	7677	7662	7660	7671	7677	7683	7681	7623
				7539	7572	7574	7571	7561	7564	7576	7586	7594	7600	7587	7576	7576	7586	7593	7598	7597	7536
				7512	7546	7548	7545	7534	7538	7550	7560	7569	7570	7553	7542	7541	7553	7560	7566	7564	7499
				7459	7492	7494	7490	7485	7484	7496	7506	7513	7506	7489	7478	7477	7489	7496	7503	7501	7431
				7435	7468	7469	7465	7455	7459	7472	7482	7486	7490	7473	7462	7466	7475	7483	7489	7489	7415
				8248	8100	8099	8091	8073	8082	8097	8110	8102	8109	8096	8084	8086	8101	8111	8119	8120	7644
				6500 6500 6500>;

			PS_Config_Lmt_FW_Rawdata_P = <
				1300 1300 1300 1300 1300 1300 1300 1300 1300 1300 1300 1300 1300 1300 1300 1300 1300 1300
				1300 1300 1300 1300 1300 1300 1300 1300 1300 1300 1300 1300 1300 1300 1300 1300 1300 1300
				1300 1300 1300 1300 1300 1300 1300 1300 1300 1300 1300 1300 1300 1300 1300 1300 1300 1300
				1300 1300 1300 1300 1300 1300 1300 1300 1300 1300 1300 1300 1300 1300 1300 1300 1300 1300
				1300 1300 1300 1300 1300 1300 1300 1300 1300 1300 1300 1300 1300 1300 1300 1300 1300 1300
				1300 1300 1300 1300 1300 1300 1300 1300 1300 1300 1300 1300 1300 1300 1300 1300 1300 1300
				1300 1300 1300 1300 1300 1300 1300 1300 1300 1300 1300 1300 1300 1300 1300 1300 1300 1300
				1300 1300 1300 1300 1300 1300 1300 1300 1300 1300 1300 1300 1300 1300 1300 1300 1300 1300
				1300 1300 1300 1300 1300 1300 1300 1300 1300 1300 1300 1300 1300 1300 1300 1300 1300 1300
				1300 1300 1300 1300 1300 1300 1300 1300 1300 1300 1300 1300 1300 1300 1300 1300 1300 1300
				1300 1300 1300 1300 1300 1300 1300 1300 1300 1300 1300 1300 1300 1300 1300 1300 1300 1300
				1300 1300 1300 1300 1300 1300 1300 1300 1300 1300 1300 1300 1300 1300 1300 1300 1300 1300
				1300 1300 1300 1300 1300 1300 1300 1300 1300 1300 1300 1300 1300 1300 1300 1300 1300 1300
				1300 1300 1300 1300 1300 1300 1300 1300 1300 1300 1300 1300 1300 1300 1300 1300 1300 1300
				1300 1300 1300 1300 1300 1300 1300 1300 1300 1300 1300 1300 1300 1300 1300 1300 1300 1300
				1300 1300 1300 1300 1300 1300 1300 1300 1300 1300 1300 1300 1300 1300 1300 1300 1300 1300
				1300 1300 1300 1300 1300 1300 1300 1300 1300 1300 1300 1300 1300 1300 1300 1300 1300 1300
				1300 1300 1300 1300 1300 1300 1300 1300 1300 1300 1300 1300 1300 1300 1300 1300 1300 1300
				1300 1300 1300 1300 1300 1300 1300 1300 1300 1300 1300 1300 1300 1300 1300 1300 1300 1300
				1300 1300 1300 1300 1300 1300 1300 1300 1300 1300 1300 1300 1300 1300 1300 1300 1300 1300
				1300 1300 1300 1300 1300 1300 1300 1300 1300 1300 1300 1300 1300 1300 1300 1300 1300 1300
				1300 1300 1300 1300 1300 1300 1300 1300 1300 1300 1300 1300 1300 1300 1300 1300 1300 1300
				1300 1300 1300 1300 1300 1300 1300 1300 1300 1300 1300 1300 1300 1300 1300 1300 1300 1300
				1300 1300 1300 1300 1300 1300 1300 1300 1300 1300 1300 1300 1300 1300 1300 1300 1300 1300
				1300 1300 1300 1300 1300 1300 1300 1300 1300 1300 1300 1300 1300 1300 1300 1300 1300 1300
				1300 1300 1300 1300 1300 1300 1300 1300 1300 1300 1300 1300 1300 1300 1300 1300 1300 1300
				1300 1300 1300 1300 1300 1300 1300 1300 1300 1300 1300 1300 1300 1300 1300 1300 1300 1300
				1300 1300 1300 1300 1300 1300 1300 1300 1300 1300 1300 1300 1300 1300 1300 1300 1300 1300
				1300 1300 1300 1300 1300 1300 1300 1300 1300 1300 1300 1300 1300 1300 1300 1300 1300 1300
				1300 1300 1300 1300 1300 1300 1300 1300 1300 1300 1300 1300 1300 1300 1300 1300 1300 1300
				1300 1300 1300 1300 1300 1300 1300 1300 1300 1300 1300 1300 1300 1300 1300 1300 1300 1300
				1300 1300 1300 1300 1300 1300 1300 1300 1300 1300 1300 1300 1300 1300 1300 1300 1300 1300
				2000 2000 2000>;

			PS_Config_Lmt_FW_Rawdata_N= <
				500 500 500 500 500 500 500 500 500 500 500 500 500 500 500 500 500 500
				500 500 500 500 500 500 500 500 500 500 500 500 500 500 500 500 500 500
				500 500 500 500 500 500 500 500 500 500 500 500 500 500 500 500 500 500
				500 500 500 500 500 500 500 500 500 500 500 500 500 500 500 500 500 500
				500 500 500 500 500 500 500 500 500 500 500 500 500 500 500 500 500 500
				500 500 500 500 500 500 500 500 500 500 500 500 500 500 500 500 500 500
				500 500 500 500 500 500 500 500 500 500 500 500 500 500 500 500 500 500
				500 500 500 500 500 500 500 500 500 500 500 500 500 500 500 500 500 500
				500 500 500 500 500 500 500 500 500 500 500 500 500 500 500 500 500 500
				500 500 500 500 500 500 500 500 500 500 500 500 500 500 500 500 500 500
				500 500 500 500 500 500 500 500 500 500 500 500 500 500 500 500 500 500
				500 500 500 500 500 500 500 500 500 500 500 500 500 500 500 500 500 500
				500 500 500 500 500 500 500 500 500 500 500 500 500 500 500 500 500 500
				500 500 500 500 500 500 500 500 500 500 500 500 500 500 500 500 500 500
				500 500 500 500 500 500 500 500 500 500 500 500 500 500 500 500 500 500
				500 500 500 500 500 500 500 500 500 500 500 500 500 500 500 500 500 500
				500 500 500 500 500 500 500 500 500 500 500 500 500 500 500 500 500 500
				500 500 500 500 500 500 500 500 500 500 500 500 500 500 500 500 500 500
				500 500 500 500 500 500 500 500 500 500 500 500 500 500 500 500 500 500
				500 500 500 500 500 500 500 500 500 500 500 500 500 500 500 500 500 500
				500 500 500 500 500 500 500 500 500 500 500 500 500 500 500 500 500 500
				500 500 500 500 500 500 500 500 500 500 500 500 500 500 500 500 500 500
				500 500 500 500 500 500 500 500 500 500 500 500 500 500 500 500 500 500
				500 500 500 500 500 500 500 500 500 500 500 500 500 500 500 500 500 500
				500 500 500 500 500 500 500 500 500 500 500 500 500 500 500 500 500 500
				500 500 500 500 500 500 500 500 500 500 500 500 500 500 500 500 500 500
				500 500 500 500 500 500 500 500 500 500 500 500 500 500 500 500 500 500
				500 500 500 500 500 500 500 500 500 500 500 500 500 500 500 500 500 500
				500 500 500 500 500 500 500 500 500 500 500 500 500 500 500 500 500 500
				500 500 500 500 500 500 500 500 500 500 500 500 500 500 500 500 500 500
				500 500 500 500 500 500 500 500 500 500 500 500 500 500 500 500 500 500
				500 500 500 500 500 500 500 500 500 500 500 500 500 500 500 500 500 500
				400 400 400>;

			PS_Config_Lmt_FW_CC_P = <116>;
			PS_Config_Lmt_FW_CC_N = <60>;
			PS_Config_Lmt_Key_FW_CC_P = <38>;
			PS_Config_Lmt_Key_FW_CC_N = <9>;

			PS_Config_Lmt_FW_CC_I_P = <25>;
			PS_Config_Lmt_FW_CC_I_N = <0>;
			PS_Config_Lmt_FW_CC_Q_P = <25>;
			PS_Config_Lmt_FW_CC_Q_N = <0>;
			PS_Config_Lmt_Key_FW_CC_I_P = <25>;
			PS_Config_Lmt_Key_FW_CC_I_N = <0>;
			PS_Config_Lmt_Key_FW_CC_Q_P = <25>;
			PS_Config_Lmt_Key_FW_CC_Q_N = <0>;

			PS_Config_Lmt_FW_Diff_P = <35>;
			PS_Config_Lmt_FW_Diff_N = <(-35)>;
			PS_Config_Lmt_Key_FW_Diff_P = <35>;
			PS_Config_Lmt_Key_FW_Diff_N = <(-35)>;

			PS_Config_Diff_Test_Frame = <50>;
		};
	};
};
